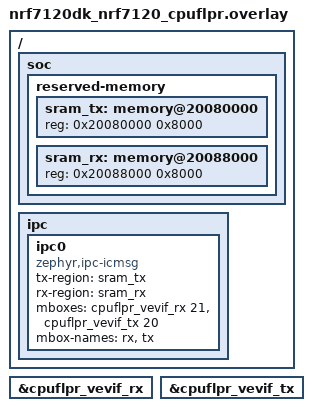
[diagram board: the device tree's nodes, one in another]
/*
 * Copyright (c) 2026 Nordic Semiconductor ASA
 *
 * SPDX-License-Identifier: LicenseRef-Nordic-5-Clause
 */

/ {
	soc {
		reserved-memory {
			#address-cells = <1>;
			#size-cells = <1>;

			sram_tx: memory@20080000 {
				reg = <0x20080000 0x8000>;
			};

			sram_rx: memory@20088000 {
				reg = <0x20088000 0x8000>;
			};
		};
	};

	ipc {
		ipc0: ipc0 {
			compatible = "zephyr,ipc-icmsg";
			tx-region = <&sram_tx>;
			rx-region = <&sram_rx>;
			mboxes = <&cpuflpr_vevif_rx 21>, <&cpuflpr_vevif_tx 20>;
			mbox-names = "rx", "tx";
			status = "okay";
		};
	};
};

&cpuflpr_vevif_rx {
	status = "okay";
};

&cpuflpr_vevif_tx {
	status = "okay";
};
